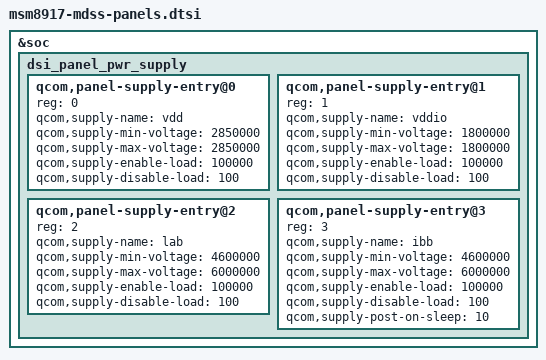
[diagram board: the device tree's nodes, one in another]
&soc {
	dsi_panel_pwr_supply: dsi_panel_pwr_supply {
		#address-cells = <1>;
		#size-cells = <0>;

		qcom,panel-supply-entry@0 {
			reg = <0>;
			qcom,supply-name = "vdd";
			qcom,supply-min-voltage = <2850000>;
			qcom,supply-max-voltage = <2850000>;
			qcom,supply-enable-load = <100000>;
			qcom,supply-disable-load = <100>;
		};

		qcom,panel-supply-entry@1 {
			reg = <1>;
			qcom,supply-name = "vddio";
			qcom,supply-min-voltage = <1800000>;
			qcom,supply-max-voltage = <1800000>;
			qcom,supply-enable-load = <100000>;
			qcom,supply-disable-load = <100>;
		};

		qcom,panel-supply-entry@2 {
			reg = <2>;
			qcom,supply-name = "lab";
			qcom,supply-min-voltage = <4600000>;
			qcom,supply-max-voltage = <6000000>;
			qcom,supply-enable-load = <100000>;
			qcom,supply-disable-load = <100>;
		};

		qcom,panel-supply-entry@3 {
			reg = <3>;
			qcom,supply-name = "ibb";
			qcom,supply-min-voltage = <4600000>;
			qcom,supply-max-voltage = <6000000>;
			qcom,supply-enable-load = <100000>;
			qcom,supply-disable-load = <100>;
			qcom,supply-post-on-sleep = <10>;
		};
	};
};
